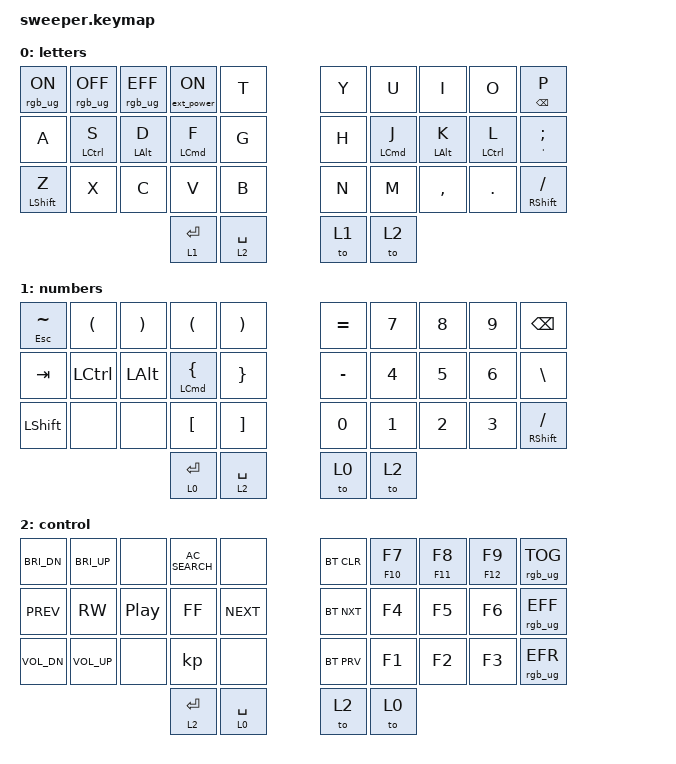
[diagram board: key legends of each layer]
/*
 * Copyright (c) 2020 The ZMK Contributors
 *
 * SPDX-License-Identifier: MIT
 */

#include <behaviors.dtsi>
#include <dt-bindings/zmk/keys.h>
#include <dt-bindings/zmk/bt.h>
#include <dt-bindings/zmk/rgb.h>
#include <dt-bindings/zmk/ext_power.h>

/ {
    macros {
        zed_em_kay: zed_em_kay {
            label = "ZM_zed_em_kay";
            compatible = "zmk,behavior-macro";
            #binding-cells = <0>;
            bindings
                = <&macro_press &kp LSHFT>
                , <&macro_tap &kp Z &kp M &kp K>
                , <&macro_release &kp LSHFT>
                ;
        };
    };
};

&mt {
  //  flavor = "tap-preferred";
   // tapping_term_ms = <200>;
};
/ {
/*
  combos {
    compatible = "zmk,combos";
    combo_esc {
      timeout-ms = <50>;
      key-positions = <0 1>;
      bindings = <&kp ESC>;
    };

    combo_tab {
      timeout-ms = <50>;
      key-positions = <10 11>;
      bindings = <&kp TAB>;
    };

    combo_ralt {
      timeout-ms = <50>;
      key-positions = <17 16>;
      bindings = <&kp RALT>;
    };

    combo_lalt {
      timeout-ms = <50>;
      key-positions = <11 12>;
      bindings = <&kp LALT>;
    };

    combo_lgui {
      timeout-ms = <50>;
      key-positions = <12 13>;
      bindings = <&kp LGUI>;
    };

    combo_rgui {
      timeout-ms = <50>;
      key-positions = <17 18>;
      bindings = <&kp RGUI>;
    };
  };
*/
  keymap {
    compatible = "zmk,keymap";

    letters {
      bindings = <

      &rgb_ug RGB_ON  &rgb_ug RGB_OFF &rgb_ug RGB_EFF &ext_power EP_ON       &kp T         &kp Y  &kp U      &kp I      &kp O       &mt BACKSPACE P
      &kp A       &mt LCTRL S &mt LALT D &mt LCMD F  &kp G         &kp H  &mt LCMD J &mt LALT K &mt LCTRL L &mt QUOT SEMI
      &mt LSHFT Z &kp X       &kp C      &kp V       &kp B         &kp N  &kp M      &kp CMMA   &kp DOT     &mt RSHFT FSLH
                                         &lt 1 ENTER &lt 2 SPACE   &to 1  &to 2

      // &mt ESC Q   &kp W       &kp E      &kp R       &kp T         &kp Y  &kp U      &kp I      &kp O       &mt BACKSPACE P
      // &kp A       &mt LCTRL S &mt LALT D &mt LCMD F  &kp G         &kp H  &mt LCMD J &mt LALT K &mt LCTRL L &mt QUOT SEMI
      // &mt LSHFT Z &kp X       &kp C      &kp V       &kp B         &kp N  &kp M      &kp CMMA   &kp DOT     &mt RSHFT FSLH
      //                                    &lt 1 ENTER &lt 2 SPACE   &to 1  &to 2
      >;
    };

    numbers {
      bindings = <
      &mt ESC TILDE &kp LPAR  &kp RPAR &kp LPAR      &kp RPAR      &kp EQUAL &kp NUM_7 &kp NUM_8 &kp NUM_9 &kp BACKSPACE
      &kp TAB       &kp LCTRL &kp LALT &mt LCMD LBRC &kp RBRC      &kp MINUS &kp NUM_4 &kp NUM_5 &kp NUM_6 &kp BSLH
      &kp LSHIFT    &none     &none    &kp LBKT      &kp RBKT      &kp NUM_0 &kp NUM_1 &kp NUM_2 &kp NUM_3 &mt RSHFT FSLH
                                       &lt 0 ENTER   &lt 2 SPACE   &to 0     &to 2
      >;
    };

    control {
      bindings = <
      &kp C_BRI_DN &kp C_BRI_UP &none    &kp C_AC_SEARCH &none         &bt BT_CLR &mt F10 F7 &mt F11 F8 &mt F12 F9 &rgb_ug RGB_TOG
      &kp C_PREV   &kp C_RW     &kp C_PP &kp C_FF        &kp C_NEXT    &bt BT_NXT &kp F4     &kp F5     &kp F6     &rgb_ug RGB_EFF
      &kp C_VOL_DN &kp C_VOL_UP &none    &kp             &none         &bt BT_PRV &kp F1     &kp F2     &kp F3     &rgb_ug RGB_EFR
                                         &lt 2 ENTER     &lt 0 SPACE   &to 2      &to 0
      >;
    };

    // function {
    //   bindings = <
    //   >;
    // };
  };
};
